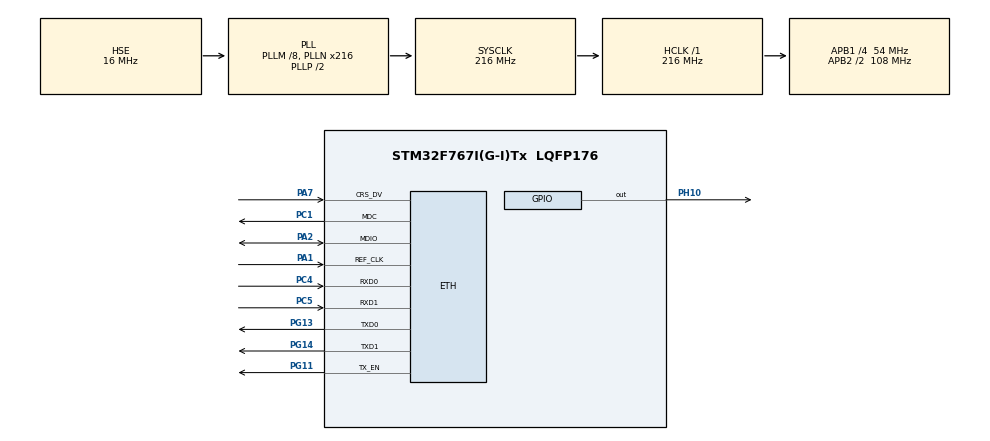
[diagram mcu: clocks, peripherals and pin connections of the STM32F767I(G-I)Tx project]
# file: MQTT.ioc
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CORTEX_M7.ART_ACCLERATOR_ENABLE=1
CORTEX_M7.AccessPermission-Cortex_Memory_Protection_Unit_Region0_Settings=MPU_REGION_FULL_ACCESS
CORTEX_M7.AccessPermission-Cortex_Memory_Protection_Unit_Region1_Settings=MPU_REGION_FULL_ACCESS
CORTEX_M7.AccessPermission-Cortex_Memory_Protection_Unit_Region2_Settings=MPU_REGION_FULL_ACCESS
CORTEX_M7.BaseAddress-Cortex_Memory_Protection_Unit_Region0_Settings=0x20000000
CORTEX_M7.BaseAddress-Cortex_Memory_Protection_Unit_Region1_Settings=0x20020000
CORTEX_M7.BaseAddress-Cortex_Memory_Protection_Unit_Region2_Settings=0x20060000
CORTEX_M7.CPU_DCache=Enabled
CORTEX_M7.CPU_ICache=Enabled
CORTEX_M7.Enable-Cortex_Memory_Protection_Unit_Region0_Settings=MPU_REGION_ENABLE
CORTEX_M7.Enable-Cortex_Memory_Protection_Unit_Region1_Settings=MPU_REGION_ENABLE
CORTEX_M7.Enable-Cortex_Memory_Protection_Unit_Region2_Settings=MPU_REGION_ENABLE
CORTEX_M7.IsBufferable-Cortex_Memory_Protection_Unit_Region0_Settings=MPU_ACCESS_BUFFERABLE
CORTEX_M7.IsBufferable-Cortex_Memory_Protection_Unit_Region1_Settings=MPU_ACCESS_BUFFERABLE
CORTEX_M7.IsBufferable-Cortex_Memory_Protection_Unit_Region2_Settings=MPU_ACCESS_BUFFERABLE
CORTEX_M7.IsCacheable-Cortex_Memory_Protection_Unit_Region0_Settings=MPU_ACCESS_CACHEABLE
CORTEX_M7.IsCacheable-Cortex_Memory_Protection_Unit_Region1_Settings=MPU_ACCESS_CACHEABLE
CORTEX_M7.IsCacheable-Cortex_Memory_Protection_Unit_Region2_Settings=MPU_ACCESS_CACHEABLE
CORTEX_M7.IsShareable-Cortex_Memory_Protection_Unit_Region0_Settings=MPU_ACCESS_SHAREABLE
CORTEX_M7.IsShareable-Cortex_Memory_Protection_Unit_Region1_Settings=MPU_ACCESS_SHAREABLE
CORTEX_M7.IsShareable-Cortex_Memory_Protection_Unit_Region2_Settings=MPU_ACCESS_SHAREABLE
CORTEX_M7.MPU_Control=MPU_HFNMI_PRIVDEF
CORTEX_M7.PREFETCH_ENABLE=1
CORTEX_M7.Size-Cortex_Memory_Protection_Unit_Region0_Settings=MPU_REGION_SIZE_128KB
CORTEX_M7.Size-Cortex_Memory_Protection_Unit_Region1_Settings=MPU_REGION_SIZE_256KB
CORTEX_M7.Size-Cortex_Memory_Protection_Unit_Region2_Settings=MPU_REGION_SIZE_128KB
ETH.MediaInterface=ETH_MEDIA_INTERFACE_RMII
ETH.PhyAddress=0
FREERTOS.Tasks01=defaultTask,0,128,StartDefaultTask,Default,NULL,Dynamic,NULL,NULL
LWIP.GATEWAY_ADDRESS=192.168.001.001
LWIP.IP_ADDRESS=192.168.001.212
LWIP.LWIP_DHCP=0
LWIP.LWIP_DNS=1
LWIP.LWIP_IPV6_FRAG=0
LWIP.LWIP_IPV6_SEND_ROUTER_SOLICIT=0
LWIP.LWIP_ND6_ALLOW_RA_UPDATES=0
LWIP.LWIP_ND6_TCP_REACHABILITY_HINTS=0
LWIP.LWIP_NETIF_EXT_STATUS_CALLBACK=1
LWIP.LWIP_NETIF_HOSTNAME=1
LWIP.LWIP_NETIF_LINK_CALLBACK=1
LWIP.LWIP_NETIF_STATUS_CALLBACK=1
LWIP.LWIP_SNTP=0
LWIP.NETMASK_ADDRESS=255.255.255.000
LWIP.Version=v2.1.2_Cube
Mcu.Family=STM32F7
Mcu.Name=STM32F767I(G-I)Tx
Mcu.Package=LQFP176
NVIC.ETH_IRQn=true\:5\:0\:false\:false\:true\:true\:true\:true
NVIC.PriorityGroup=NVIC_PRIORITYGROUP_4
NVIC.TIM1_UP_TIM10_IRQn=true\:0\:0\:false\:false\:true\:false\:false\:true
NVIC.TimeBase=TIM1_UP_TIM10_IRQn
NVIC.TimeBaseIP=TIM1
PA1.Mode=RMII
PA1.Signal=ETH_REF_CLK
PA13.Mode=Serial_Wire
PA13.Signal=SYS_JTMS-SWDIO
PA14.Mode=Serial_Wire
PA14.Signal=SYS_JTCK-SWCLK
PA2.Mode=RMII
PA2.Signal=ETH_MDIO
PA7.Mode=RMII
PA7.Signal=ETH_CRS_DV
PC1.Mode=RMII
PC1.Signal=ETH_MDC
PC14/OSC32_IN.Mode=LSE-External-Oscillator
PC14/OSC32_IN.Signal=RCC_OSC32_IN
PC15/OSC32_OUT.Mode=LSE-External-Oscillator
PC15/OSC32_OUT.Signal=RCC_OSC32_OUT
PC4.Mode=RMII
PC4.Signal=ETH_RXD0
PC5.Mode=RMII
PC5.Signal=ETH_RXD1
PG11.Mode=RMII
PG11.Signal=ETH_TX_EN
PG13.Mode=RMII
PG13.Signal=ETH_TXD0
PG14.Mode=RMII
PG14.Signal=ETH_TXD1
PH0/OSC_IN.Mode=HSE-External-Oscillator
PH0/OSC_IN.Signal=RCC_OSC_IN
PH1/OSC_OUT.Mode=HSE-External-Oscillator
PH1/OSC_OUT.Signal=RCC_OSC_OUT
PH10.PinState=GPIO_PIN_SET
PH10.Signal=GPIO_Output
ProjectManager.HeapSize=0x1000
ProjectManager.StackSize=0x2000
ProjectManager.TargetToolchain=MDK-ARM V5.27
RCC.AHBFreq_Value=216000000
RCC.APB1CLKDivider=RCC_HCLK_DIV4
RCC.APB1Freq_Value=54000000
RCC.APB1TimFreq_Value=108000000
RCC.APB2CLKDivider=RCC_HCLK_DIV2
RCC.APB2Freq_Value=108000000
RCC.APB2TimFreq_Value=216000000
RCC.CortexFreq_Value=216000000
RCC.HCLKFreq_Value=216000000
RCC.HSE_VALUE=16000000
RCC.HSI_VALUE=16000000
RCC.PLLM=8
RCC.PLLN=216
RCC.PLLQ=9
RCC.PLLSourceVirtual=RCC_PLLSOURCE_HSE
RCC.RTCClockSelection=RCC_RTCCLKSOURCE_LSE
RCC.SDMMCClockSelection=RCC_SDMMC1CLKSOURCE_CLK48
RCC.SYSCLKFreq_VALUE=216000000
RCC.SYSCLKSource=RCC_SYSCLKSOURCE_PLLCLK
RCC.USBFreq_Value=48000000
RCC.VCOOutputFreq_Value=432000000
VP_FREERTOS_VS_CMSIS_V1.Mode=CMSIS_V1
VP_LWIP_VS_Enabled.Mode=Enabled
VP_RNG_VS_RNG.Mode=RNG_Activate
VP_SYS_VS_tim1.Mode=TIM1
board=custom

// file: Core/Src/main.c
/* USER CODE BEGIN Header */
/**
  ******************************************************************************
  * @file           : main.c
  * @brief          : Main program body
  ******************************************************************************
  * @attention
  *
  * <h2><center>&copy; Copyright (c) 2020 STMicroelectronics.
  * All rights reserved.</center></h2>
  *
  * This software component is licensed by ST under Ultimate Liberty license
  * SLA0044, the "License"; You may not use this file except in compliance with
  * the License. You may obtain a copy of the License at:
  *                             www.st.com/SLA0044
  *
  ******************************************************************************
  */
/* USER CODE END Header */

#include "main.h"
#include "cmsis_os.h"
#include "lwip.h"
#include "rng.h"
#include "gpio.h"

void SystemClock_Config(void);
static void MPU_Config(void);
void MX_FREERTOS_Init(void);

int main(void)
{

  /* MPU Configuration--------------------------------------------------------*/
  MPU_Config();

  /* Enable I-Cache---------------------------------------------------------*/
  SCB_EnableICache();

  /* Enable D-Cache---------------------------------------------------------*/
  SCB_EnableDCache();

  /* MCU Configuration--------------------------------------------------------*/

  /* Reset of all peripherals, Initializes the Flash interface and the Systick. */
  HAL_Init();

  /* Configure the system clock */
  SystemClock_Config();

  /* Initialize all configured peripherals */
  MX_GPIO_Init();
  MX_RNG_Init();

  /* Call init function for freertos objects (in freertos.c) */
  MX_FREERTOS_Init();
  /* Start scheduler */
  osKernelStart();

  /* We should never get here as control is now taken by the scheduler */
  /* Infinite loop */
  while (1)
  {

  }
}

void SystemClock_Config(void)
{
  RCC_OscInitTypeDef RCC_OscInitStruct = {0};
  RCC_ClkInitTypeDef RCC_ClkInitStruct = {0};
  RCC_PeriphCLKInitTypeDef PeriphClkInitStruct = {0};

  /** Configure LSE Drive Capability
  */
  HAL_PWR_EnableBkUpAccess();
  /** Configure the main internal regulator output voltage
  */
  __HAL_RCC_PWR_CLK_ENABLE();
  __HAL_PWR_VOLTAGESCALING_CONFIG(PWR_REGULATOR_VOLTAGE_SCALE1);
  /** Initializes the CPU, AHB and APB busses clocks
  */
  RCC_OscInitStruct.OscillatorType = RCC_OSCILLATORTYPE_HSE;
  RCC_OscInitStruct.HSEState = RCC_HSE_ON;
  RCC_OscInitStruct.PLL.PLLState = RCC_PLL_ON;
  RCC_OscInitStruct.PLL.PLLSource = RCC_PLLSOURCE_HSE;
  RCC_OscInitStruct.PLL.PLLM = 8;
  RCC_OscInitStruct.PLL.PLLN = 216;
  RCC_OscInitStruct.PLL.PLLP = RCC_PLLP_DIV2;
  RCC_OscInitStruct.PLL.PLLQ = 9;
  if (HAL_RCC_OscConfig(&RCC_OscInitStruct) != HAL_OK)
  {
    Error_Handler();
  }
  /** Activate the Over-Drive mode
  */
  if (HAL_PWREx_EnableOverDrive() != HAL_OK)
  {
    Error_Handler();
  }
  /** Initializes the CPU, AHB and APB busses clocks
  */
  RCC_ClkInitStruct.ClockType = RCC_CLOCKTYPE_HCLK|RCC_CLOCKTYPE_SYSCLK
                              |RCC_CLOCKTYPE_PCLK1|RCC_CLOCKTYPE_PCLK2;
  RCC_ClkInitStruct.SYSCLKSource = RCC_SYSCLKSOURCE_PLLCLK;
  RCC_ClkInitStruct.AHBCLKDivider = RCC_SYSCLK_DIV1;
  RCC_ClkInitStruct.APB1CLKDivider = RCC_HCLK_DIV4;
  RCC_ClkInitStruct.APB2CLKDivider = RCC_HCLK_DIV2;

  if (HAL_RCC_ClockConfig(&RCC_ClkInitStruct, FLASH_LATENCY_7) != HAL_OK)
  {
    Error_Handler();
  }
  PeriphClkInitStruct.PeriphClockSelection = RCC_PERIPHCLK_CLK48;
  PeriphClkInitStruct.Clk48ClockSelection = RCC_CLK48SOURCE_PLL;
  if (HAL_RCCEx_PeriphCLKConfig(&PeriphClkInitStruct) != HAL_OK)
  {
    Error_Handler();
  }
}

/* MPU Configuration */

void MPU_Config(void)
{
  MPU_Region_InitTypeDef MPU_InitStruct = {0};

  /* Disables the MPU */
  HAL_MPU_Disable();
  /** Initializes and configures the Region and the memory to be protected
  */
  MPU_InitStruct.Enable = MPU_REGION_ENABLE;
  MPU_InitStruct.Number = MPU_REGION_NUMBER0;
  MPU_InitStruct.BaseAddress = 0x20000000;
  MPU_InitStruct.Size = MPU_REGION_SIZE_128KB;
  MPU_InitStruct.SubRegionDisable = 0x0;
  MPU_InitStruct.TypeExtField = MPU_TEX_LEVEL0;
  MPU_InitStruct.AccessPermission = MPU_REGION_FULL_ACCESS;
  MPU_InitStruct.DisableExec = MPU_INSTRUCTION_ACCESS_ENABLE;
  MPU_InitStruct.IsShareable = MPU_ACCESS_SHAREABLE;
  MPU_InitStruct.IsCacheable = MPU_ACCESS_CACHEABLE;
  MPU_InitStruct.IsBufferable = MPU_ACCESS_BUFFERABLE;

  HAL_MPU_ConfigRegion(&MPU_InitStruct);
  /** Initializes and configures the Region and the memory to be protected
  */
  MPU_InitStruct.Enable = MPU_REGION_ENABLE;
  MPU_InitStruct.Number = MPU_REGION_NUMBER1;
  MPU_InitStruct.BaseAddress = 0x20020000;
  MPU_InitStruct.Size = MPU_REGION_SIZE_256KB;
  MPU_InitStruct.SubRegionDisable = 0x0;
  MPU_InitStruct.TypeExtField = MPU_TEX_LEVEL0;
  MPU_InitStruct.AccessPermission = MPU_REGION_FULL_ACCESS;
  MPU_InitStruct.DisableExec = MPU_INSTRUCTION_ACCESS_ENABLE;
  MPU_InitStruct.IsShareable = MPU_ACCESS_SHAREABLE;
  MPU_InitStruct.IsCacheable = MPU_ACCESS_CACHEABLE;
  MPU_InitStruct.IsBufferable = MPU_ACCESS_BUFFERABLE;

  HAL_MPU_ConfigRegion(&MPU_InitStruct);
  /** Initializes and configures the Region and the memory to be protected
  */
  MPU_InitStruct.Enable = MPU_REGION_ENABLE;
  MPU_InitStruct.Number = MPU_REGION_NUMBER2;
  MPU_InitStruct.BaseAddress = 0x20060000;
  MPU_InitStruct.Size = MPU_REGION_SIZE_128KB;
  MPU_InitStruct.SubRegionDisable = 0x0;
  MPU_InitStruct.TypeExtField = MPU_TEX_LEVEL0;
  MPU_InitStruct.AccessPermission = MPU_REGION_FULL_ACCESS;
  MPU_InitStruct.DisableExec = MPU_INSTRUCTION_ACCESS_ENABLE;
  MPU_InitStruct.IsShareable = MPU_ACCESS_SHAREABLE;
  MPU_InitStruct.IsCacheable = MPU_ACCESS_CACHEABLE;
  MPU_InitStruct.IsBufferable = MPU_ACCESS_BUFFERABLE;

  HAL_MPU_ConfigRegion(&MPU_InitStruct);
  /* Enables the MPU */
  HAL_MPU_Enable(MPU_HFNMI_PRIVDEF);

}
void HAL_TIM_PeriodElapsedCallback(TIM_HandleTypeDef *htim)
{
  if (htim->Instance == TIM1) {
    HAL_IncTick();
  }
}

void Error_Handler(void)
{
}

/************************ (C) COPYRIGHT STMicroelectronics *****END OF FILE****/

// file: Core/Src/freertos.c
/* USER CODE BEGIN Header */
/**
  ******************************************************************************
  * File Name          : freertos.c
  * Description        : Code for freertos applications
  ******************************************************************************
  * @attention
  *
  * <h2><center>&copy; Copyright (c) 2020 STMicroelectronics.
  * All rights reserved.</center></h2>
  *
  * This software component is licensed by ST under Ultimate Liberty license
  * SLA0044, the "License"; You may not use this file except in compliance with
  * the License. You may obtain a copy of the License at:
  *                             www.st.com/SLA0044
  *
  ******************************************************************************
  */
/* USER CODE END Header */

#include "FreeRTOS.h"
#include "task.h"
#include "main.h"
#include "cmsis_os.h"

/* USER CODE BEGIN Includes */
#include "bsp_printlog.h"
#include "bsp_mqtt.h"
/* USER CODE END Includes */

osThreadId defaultTaskHandle;

void StartDefaultTask(void const * argument);

extern void MX_LWIP_Init(void);
void MX_FREERTOS_Init(void); /* (MISRA C 2004 rule 8.1) */

/* GetIdleTaskMemory prototype (linked to static allocation support) */
void vApplicationGetIdleTaskMemory( StaticTask_t **ppxIdleTaskTCBBuffer, StackType_t **ppxIdleTaskStackBuffer, uint32_t *pulIdleTaskStackSize );

/* USER CODE BEGIN GET_IDLE_TASK_MEMORY */
static StaticTask_t xIdleTaskTCBBuffer;
static StackType_t xIdleStack[configMINIMAL_STACK_SIZE];

void vApplicationGetIdleTaskMemory( StaticTask_t **ppxIdleTaskTCBBuffer, StackType_t **ppxIdleTaskStackBuffer, uint32_t *pulIdleTaskStackSize )
{
  *ppxIdleTaskTCBBuffer = &xIdleTaskTCBBuffer;
  *ppxIdleTaskStackBuffer = &xIdleStack[0];
  *pulIdleTaskStackSize = configMINIMAL_STACK_SIZE;
  /* place for user code */
}
/* USER CODE END GET_IDLE_TASK_MEMORY */

void MX_FREERTOS_Init(void) {
  /* USER CODE BEGIN Init */
       segger_rtt_init("Demo start!");
  /* USER CODE END Init */

  /* Create the thread(s) */
  /* definition and creation of defaultTask */
  osThreadDef(defaultTask, StartDefaultTask, osPriorityNormal, 0, 1024);
  defaultTaskHandle = osThreadCreate(osThread(defaultTask), NULL);

}

void StartDefaultTask(void const * argument)
{
  /* init code for LWIP */
  MX_LWIP_Init();
  /* USER CODE BEGIN StartDefaultTask */

    bsp_mqtt_init();

  /* Infinite loop */
  for(;;)
  {
    osDelay(1);
  }
  /* USER CODE END StartDefaultTask */
}

/************************ (C) COPYRIGHT STMicroelectronics *****END OF FILE****/
